# PIC32MX695F512L register map
Registers are 32-bit, access not given, reset 0x0 unless marked. A register's access mark holds for its fields unless they carry their own. Offsets are from the block's base; [hi:lo] are bit positions; {n}, {i} and the like mark numbered series; 'fields as' and 'values as' point back to an identical list.

## PCACHE — PCACHE peripheral
Base 0xBF884000
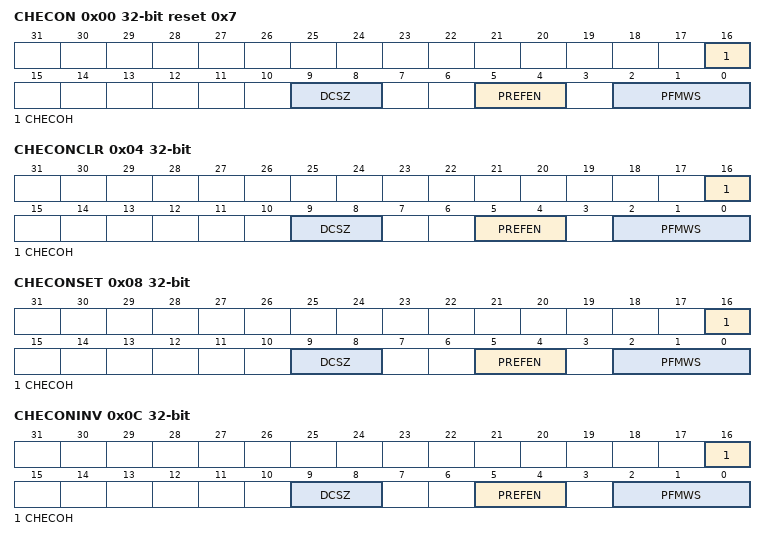
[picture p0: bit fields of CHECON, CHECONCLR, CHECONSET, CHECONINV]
0x00 CHECON reset 0x7
  [16] CHECOH, [9:8] DCSZ, [5:4] PREFEN, [2:0] PFMWS
0x04 CHECONCLR
  [16] CHECOH, [9:8] DCSZ, [5:4] PREFEN, [2:0] PFMWS
0x08 CHECONSET
  [16] CHECOH, [9:8] DCSZ, [5:4] PREFEN, [2:0] PFMWS
0x0C CHECONINV
  [16] CHECOH, [9:8] DCSZ, [5:4] PREFEN, [2:0] PFMWS
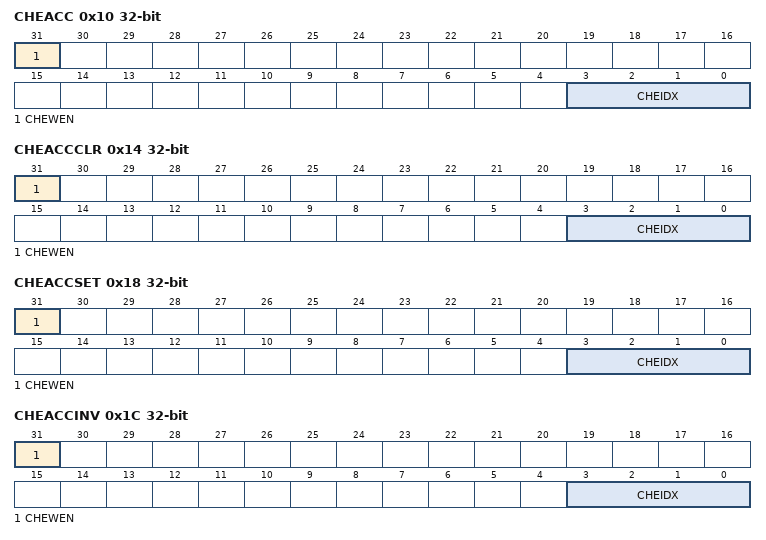
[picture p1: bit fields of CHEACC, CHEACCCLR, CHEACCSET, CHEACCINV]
0x10 CHEACC
  [31] CHEWEN, [3:0] CHEIDX
0x14 CHEACCCLR
  [31] CHEWEN, [3:0] CHEIDX
0x18 CHEACCSET
  [31] CHEWEN, [3:0] CHEIDX
0x1C CHEACCINV
  [31] CHEWEN, [3:0] CHEIDX
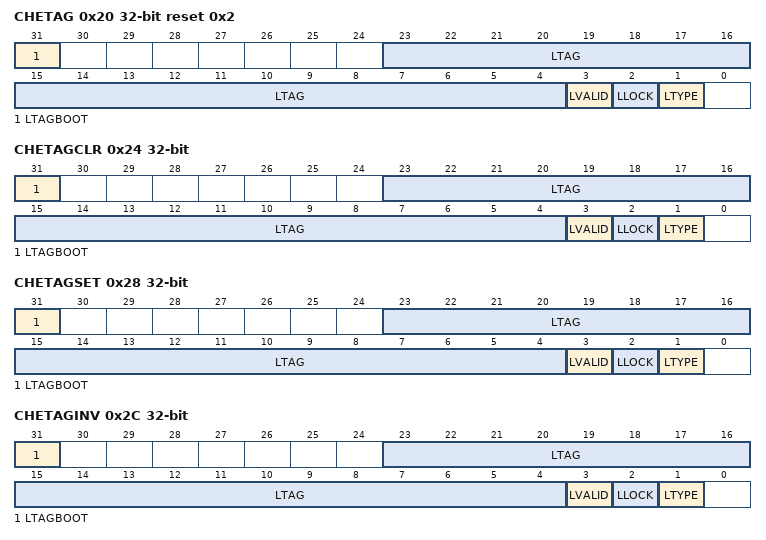
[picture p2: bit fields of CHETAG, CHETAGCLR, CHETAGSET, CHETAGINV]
0x20 CHETAG reset 0x2
  [31] LTAGBOOT, [23:4] LTAG, [3] LVALID, [2] LLOCK, [1] LTYPE
0x24 CHETAGCLR
  [31] LTAGBOOT, [23:4] LTAG, [3] LVALID, [2] LLOCK, [1] LTYPE
0x28 CHETAGSET
  [31] LTAGBOOT, [23:4] LTAG, [3] LVALID, [2] LLOCK, [1] LTYPE
0x2C CHETAGINV
  [31] LTAGBOOT, [23:4] LTAG, [3] LVALID, [2] LLOCK, [1] LTYPE
0x30 CHEMSK
  [15:5] LMASK
0x34 CHEMSKCLR
  [15:5] LMASK
0x38 CHEMSKSET
  [15:5] LMASK
0x3C CHEMSKINV
  [15:5] LMASK
{0x40+0x10*i} CHEW{i} (i=0..3)
0x80 CHELRU
  [24:0] CHELRU
0x90 CHEHIT
0xA0 CHEMIS
0xC0 CHEPFABT

## PORTA — PORTA peripheral
Base 0xBF886000
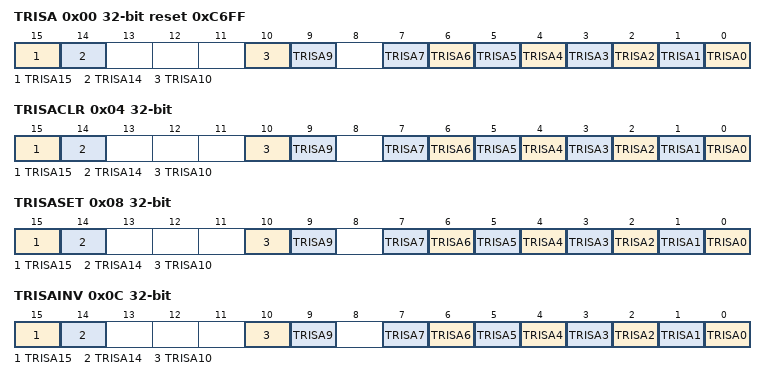
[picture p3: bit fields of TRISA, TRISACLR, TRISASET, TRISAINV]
0x00 TRISA reset 0xC6FF
  [15] TRISA15, [14] TRISA14, [10] TRISA10, [9] TRISA9, [n] TRISA{n} (n=0..7)
0x04 TRISACLR
  fields as TRISA
0x08 TRISASET
  fields as TRISA
0x0C TRISAINV
  fields as TRISA
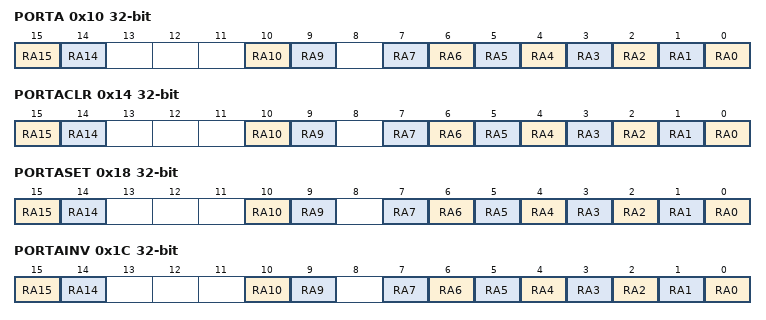
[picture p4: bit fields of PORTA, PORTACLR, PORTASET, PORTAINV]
0x10 PORTA
  [15] RA15, [14] RA14, [10] RA10, [9] RA9, [n] RA{n} (n=0..7)
0x14 PORTACLR
  [15] RA15, [14] RA14, [10] RA10, [9] RA9, [n] RA{n} (n=0..7)
0x18 PORTASET
  [15] RA15, [14] RA14, [10] RA10, [9] RA9, [n] RA{n} (n=0..7)
0x1C PORTAINV
  [15] RA15, [14] RA14, [10] RA10, [9] RA9, [n] RA{n} (n=0..7)
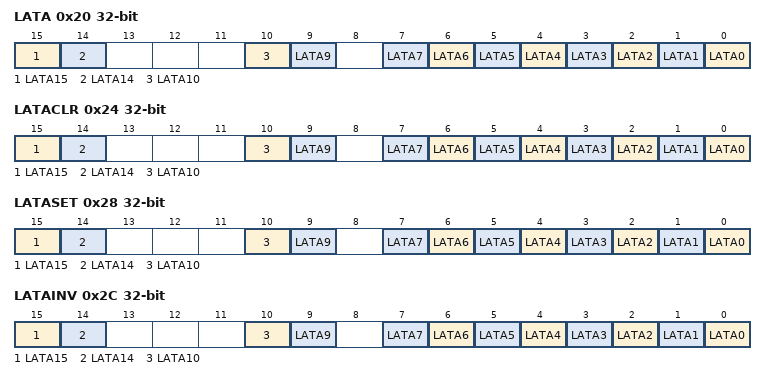
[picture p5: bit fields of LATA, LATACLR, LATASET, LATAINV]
0x20 LATA
  [15] LATA15, [14] LATA14, [10] LATA10, [9] LATA9, [n] LATA{n} (n=0..7)
0x24 LATACLR
  fields as LATA
0x28 LATASET
  fields as LATA
0x2C LATAINV
  fields as LATA
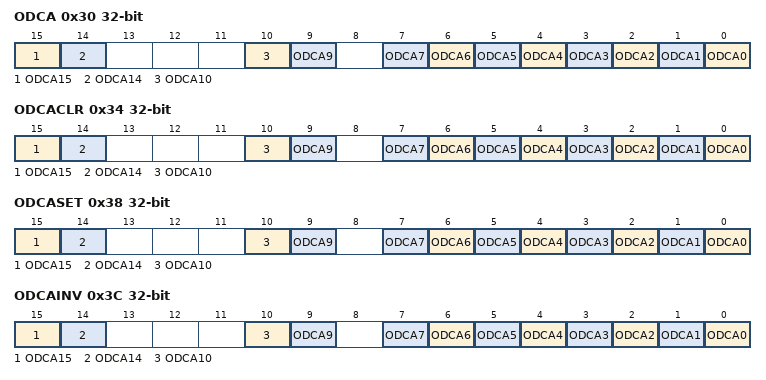
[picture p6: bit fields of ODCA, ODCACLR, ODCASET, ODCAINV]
0x30 ODCA
  [15] ODCA15, [14] ODCA14, [10] ODCA10, [9] ODCA9, [n] ODCA{n} (n=0..7)
0x34 ODCACLR
  fields as ODCA
0x38 ODCASET
  fields as ODCA
0x3C ODCAINV
  fields as ODCA

## PORTB — PORTB peripheral
Base 0xBF886040
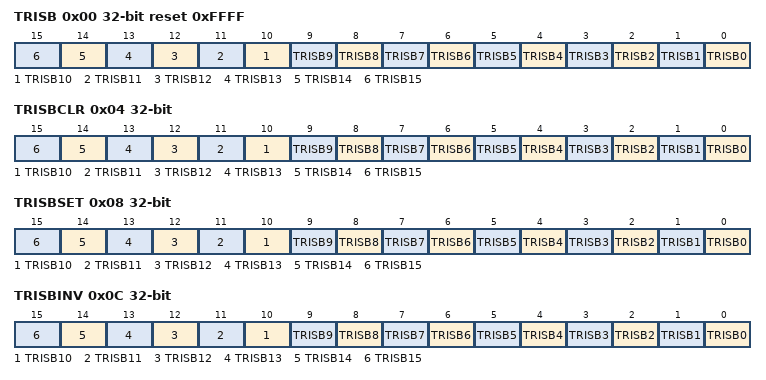
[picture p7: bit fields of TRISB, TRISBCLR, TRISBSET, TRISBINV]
0x00 TRISB reset 0xFFFF
  [n] TRISB{n} (n=0..15)
0x04 TRISBCLR
  [n] TRISB{n} (n=0..15)
0x08 TRISBSET
  [n] TRISB{n} (n=0..15)
0x0C TRISBINV
  [n] TRISB{n} (n=0..15)
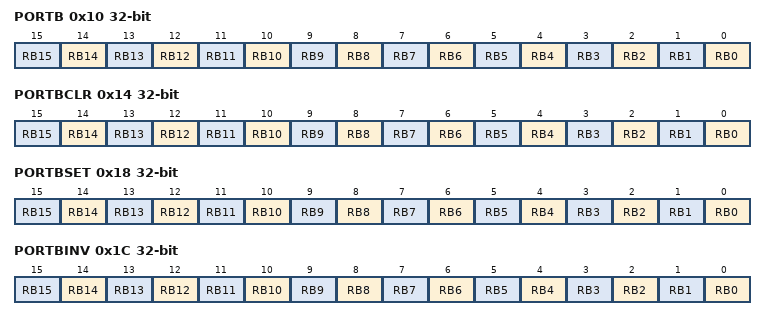
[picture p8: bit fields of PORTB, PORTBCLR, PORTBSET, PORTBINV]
0x10 PORTB
  [n] RB{n} (n=0..15)
0x14 PORTBCLR
  [n] RB{n} (n=0..15)
0x18 PORTBSET
  [n] RB{n} (n=0..15)
0x1C PORTBINV
  [n] RB{n} (n=0..15)
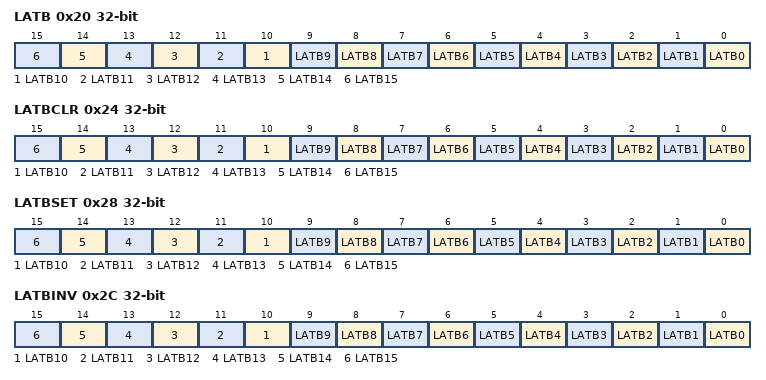
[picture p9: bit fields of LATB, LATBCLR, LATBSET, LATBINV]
0x20 LATB
  [n] LATB{n} (n=0..15)
0x24 LATBCLR
  [n] LATB{n} (n=0..15)
0x28 LATBSET
  [n] LATB{n} (n=0..15)
0x2C LATBINV
  [n] LATB{n} (n=0..15)
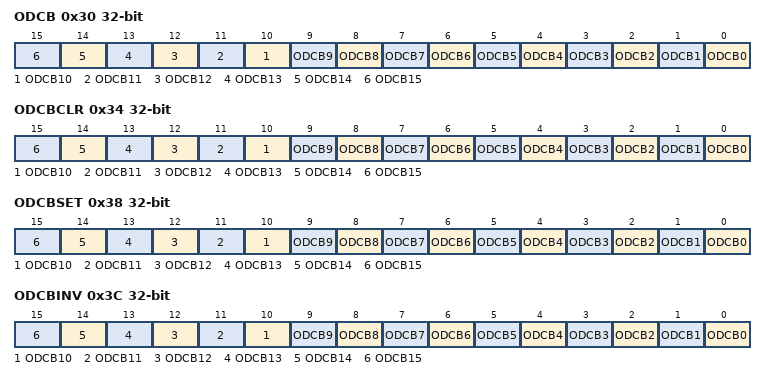
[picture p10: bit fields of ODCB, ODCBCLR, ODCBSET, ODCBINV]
0x30 ODCB
  [n] ODCB{n} (n=0..15)
0x34 ODCBCLR
  [n] ODCB{n} (n=0..15)
0x38 ODCBSET
  [n] ODCB{n} (n=0..15)
0x3C ODCBINV
  [n] ODCB{n} (n=0..15)

## PORTC — PORTC peripheral
Base 0xBF886080
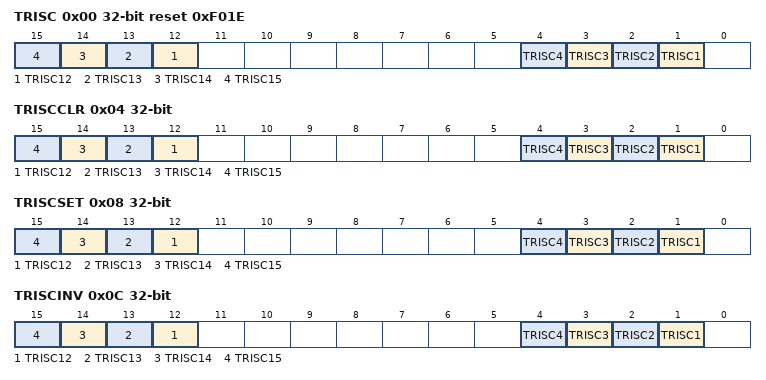
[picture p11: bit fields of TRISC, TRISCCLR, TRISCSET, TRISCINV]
0x00 TRISC reset 0xF01E
  [n] TRISC{n} (n=12..15), [n] TRISC{n} (n=1..4)
0x04 TRISCCLR
  [n] TRISC{n} (n=12..15), [n] TRISC{n} (n=1..4)
0x08 TRISCSET
  [n] TRISC{n} (n=12..15), [n] TRISC{n} (n=1..4)
0x0C TRISCINV
  [n] TRISC{n} (n=12..15), [n] TRISC{n} (n=1..4)
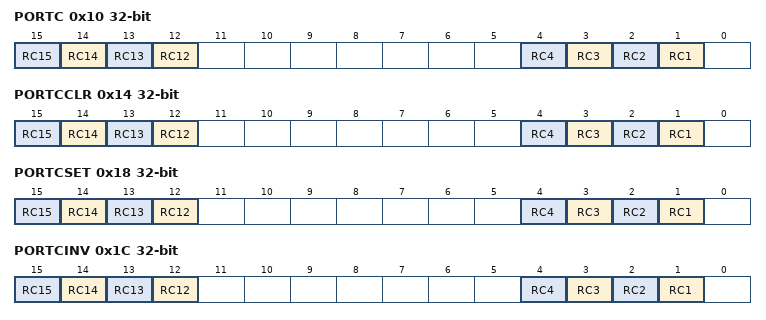
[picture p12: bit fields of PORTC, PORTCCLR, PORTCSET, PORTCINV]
0x10 PORTC
  [n] RC{n} (n=12..15), [n] RC{n} (n=1..4)
0x14 PORTCCLR
  [n] RC{n} (n=12..15), [n] RC{n} (n=1..4)
0x18 PORTCSET
  [n] RC{n} (n=12..15), [n] RC{n} (n=1..4)
0x1C PORTCINV
  [n] RC{n} (n=12..15), [n] RC{n} (n=1..4)
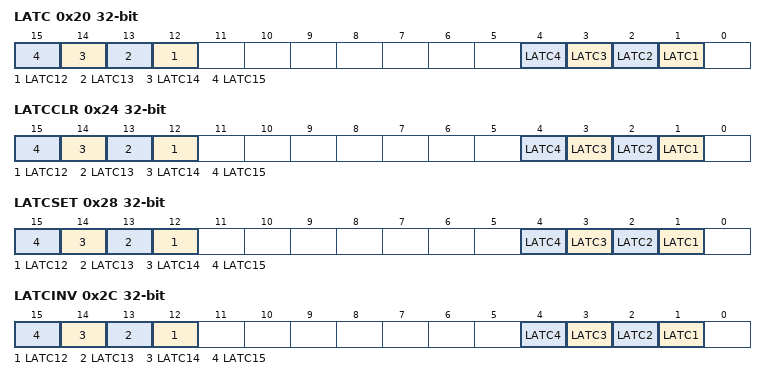
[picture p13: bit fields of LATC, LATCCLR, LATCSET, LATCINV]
0x20 LATC
  [n] LATC{n} (n=12..15), [n] LATC{n} (n=1..4)
0x24 LATCCLR
  [n] LATC{n} (n=12..15), [n] LATC{n} (n=1..4)
0x28 LATCSET
  [n] LATC{n} (n=12..15), [n] LATC{n} (n=1..4)
0x2C LATCINV
  [n] LATC{n} (n=12..15), [n] LATC{n} (n=1..4)
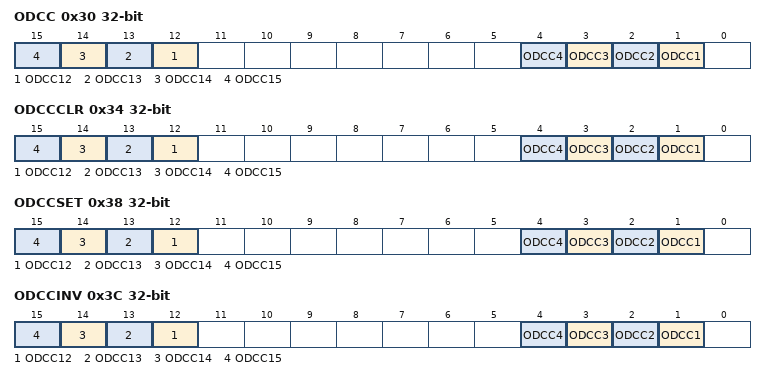
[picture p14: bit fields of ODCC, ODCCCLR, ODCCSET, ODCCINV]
0x30 ODCC
  [n] ODCC{n} (n=12..15), [n] ODCC{n} (n=1..4)
0x34 ODCCCLR
  [n] ODCC{n} (n=12..15), [n] ODCC{n} (n=1..4)
0x38 ODCCSET
  [n] ODCC{n} (n=12..15), [n] ODCC{n} (n=1..4)
0x3C ODCCINV
  [n] ODCC{n} (n=12..15), [n] ODCC{n} (n=1..4)

## PORTD — PORTD peripheral
Base 0xBF8860C0
0x00 TRISD reset 0xFFFF
  [n] TRISD{n} (n=0..15)
0x04 TRISDCLR
  [n] TRISD{n} (n=0..15)
0x08 TRISDSET
  [n] TRISD{n} (n=0..15)
0x0C TRISDINV
  [n] TRISD{n} (n=0..15)
0x10 PORTD
  [n] RD{n} (n=0..15)
0x14 PORTDCLR
  [n] RD{n} (n=0..15)
0x18 PORTDSET
  [n] RD{n} (n=0..15)
0x1C PORTDINV
  [n] RD{n} (n=0..15)
0x20 LATD
  [n] LATD{n} (n=0..15)
0x24 LATDCLR
  [n] LATD{n} (n=0..15)
0x28 LATDSET
  [n] LATD{n} (n=0..15)
0x2C LATDINV
  [n] LATD{n} (n=0..15)
0x30 ODCD
  [n] ODCD{n} (n=0..15)
0x34 ODCDCLR
  [n] ODCD{n} (n=0..15)
0x38 ODCDSET
  [n] ODCD{n} (n=0..15)
0x3C ODCDINV
  [n] ODCD{n} (n=0..15)

## PORTE — PORTE peripheral
Base 0xBF886100
0x00 TRISE reset 0x3FF
  [n] TRISE{n} (n=0..9)
0x04 TRISECLR
  [n] TRISE{n} (n=0..9)
0x08 TRISESET
  [n] TRISE{n} (n=0..9)
0x0C TRISEINV
  [n] TRISE{n} (n=0..9)
0x10 PORTE
  [n] RE{n} (n=0..9)
0x14 PORTECLR
  [n] RE{n} (n=0..9)
0x18 PORTESET
  [n] RE{n} (n=0..9)
0x1C PORTEINV
  [n] RE{n} (n=0..9)
0x20 LATE
  [n] LATE{n} (n=0..9)
0x24 LATECLR
  [n] LATE{n} (n=0..9)
0x28 LATESET
  [n] LATE{n} (n=0..9)
0x2C LATEINV
  [n] LATE{n} (n=0..9)
0x30 ODCE
  [n] ODCE{n} (n=0..9)
0x34 ODCECLR
  [n] ODCE{n} (n=0..9)
0x38 ODCESET
  [n] ODCE{n} (n=0..9)
0x3C ODCEINV
  [n] ODCE{n} (n=0..9)

## PORTF — PORTF peripheral
Base 0xBF886140
0x00 TRISF reset 0x313F
  [13] TRISF13, [12] TRISF12, [8] TRISF8, [n] TRISF{n} (n=0..5)
0x04 TRISFCLR
  [13] TRISF13, [12] TRISF12, [8] TRISF8, [n] TRISF{n} (n=0..5)
0x08 TRISFSET
  [13] TRISF13, [12] TRISF12, [8] TRISF8, [n] TRISF{n} (n=0..5)
0x0C TRISFINV
  [13] TRISF13, [12] TRISF12, [8] TRISF8, [n] TRISF{n} (n=0..5)
0x10 PORTF
  [13] RF13, [12] RF12, [8] RF8, [n] RF{n} (n=0..5)
0x14 PORTFCLR
  [13] RF13, [12] RF12, [8] RF8, [n] RF{n} (n=0..5)
0x18 PORTFSET
  [13] RF13, [12] RF12, [8] RF8, [n] RF{n} (n=0..5)
0x1C PORTFINV
  [13] RF13, [12] RF12, [8] RF8, [n] RF{n} (n=0..5)
0x20 LATF
  [13] LATF13, [12] LATF12, [8] LATF8, [n] LATF{n} (n=0..5)
0x24 LATFCLR
  [13] LATF13, [12] LATF12, [8] LATF8, [n] LATF{n} (n=0..5)
0x28 LATFSET
  [13] LATF13, [12] LATF12, [8] LATF8, [n] LATF{n} (n=0..5)
0x2C LATFINV
  [13] LATF13, [12] LATF12, [8] LATF8, [n] LATF{n} (n=0..5)
0x30 ODCF
  [13] ODCF13, [12] ODCF12, [8] ODCF8, [n] ODCF{n} (n=0..5)
0x34 ODCFCLR
  [13] ODCF13, [12] ODCF12, [8] ODCF8, [n] ODCF{n} (n=0..5)
0x38 ODCFSET
  [13] ODCF13, [12] ODCF12, [8] ODCF8, [n] ODCF{n} (n=0..5)
0x3C ODCFINV
  [13] ODCF13, [12] ODCF12, [8] ODCF8, [n] ODCF{n} (n=0..5)

## PORTG — PORTG peripheral
Base 0xBF886180
0x00 TRISG reset 0xF3CF
  [n] TRISG{n} (n=12..15), [n] TRISG{n} (n=6..9), [n] TRISG{n} (n=0..3)
0x04 TRISGCLR
  fields as TRISG
0x08 TRISGSET
  fields as TRISG
0x0C TRISGINV
  fields as TRISG
0x10 PORTG
  [n] RG{n} (n=12..15), [n] RG{n} (n=6..9), [n] RG{n} (n=0..3)
0x14 PORTGCLR
  [n] RG{n} (n=12..15), [n] RG{n} (n=6..9), [n] RG{n} (n=0..3)
0x18 PORTGSET
  [n] RG{n} (n=12..15), [n] RG{n} (n=6..9), [n] RG{n} (n=0..3)
0x1C PORTGINV
  [n] RG{n} (n=12..15), [n] RG{n} (n=6..9), [n] RG{n} (n=0..3)
0x20 LATG
  [n] LATG{n} (n=12..15), [n] LATG{n} (n=6..9), [n] LATG{n} (n=0..3)
0x24 LATGCLR
  [n] LATG{n} (n=12..15), [n] LATG{n} (n=6..9), [n] LATG{n} (n=0..3)
0x28 LATGSET
  [n] LATG{n} (n=12..15), [n] LATG{n} (n=6..9), [n] LATG{n} (n=0..3)
0x2C LATGINV
  [n] LATG{n} (n=12..15), [n] LATG{n} (n=6..9), [n] LATG{n} (n=0..3)
0x30 ODCG
  [n] ODCG{n} (n=12..15), [n] ODCG{n} (n=6..9), [n] ODCG{n} (n=0..3)
0x34 ODCGCLR
  [n] ODCG{n} (n=12..15), [n] ODCG{n} (n=6..9), [n] ODCG{n} (n=0..3)
0x38 ODCGSET
  [n] ODCG{n} (n=12..15), [n] ODCG{n} (n=6..9), [n] ODCG{n} (n=0..3)
0x3C ODCGINV
  [n] ODCG{n} (n=12..15), [n] ODCG{n} (n=6..9), [n] ODCG{n} (n=0..3)
0x40 CNCON
  [15] ON, [14] FRZ, [13] SIDL
0x44 CNCONCLR
  [15] ON, [14] FRZ, [13] SIDL
0x48 CNCONSET
  [15] ON, [14] FRZ, [13] SIDL
0x4C CNCONINV
  [15] ON, [14] FRZ, [13] SIDL
0x50 CNEN
  [n] CNEN{n} (n=0..21)
0x54 CNENCLR
  [n] CNEN{n} (n=0..21)
0x58 CNENSET
  [n] CNEN{n} (n=0..21)
0x5C CNENINV
  [n] CNEN{n} (n=0..21)
0x60 CNPUE
  [n] CNPUE{n} (n=0..21)
0x64 CNPUECLR
  [n] CNPUE{n} (n=0..21)
0x68 CNPUESET
  [n] CNPUE{n} (n=0..21)
0x6C CNPUEINV
  [n] CNPUE{n} (n=0..21)
